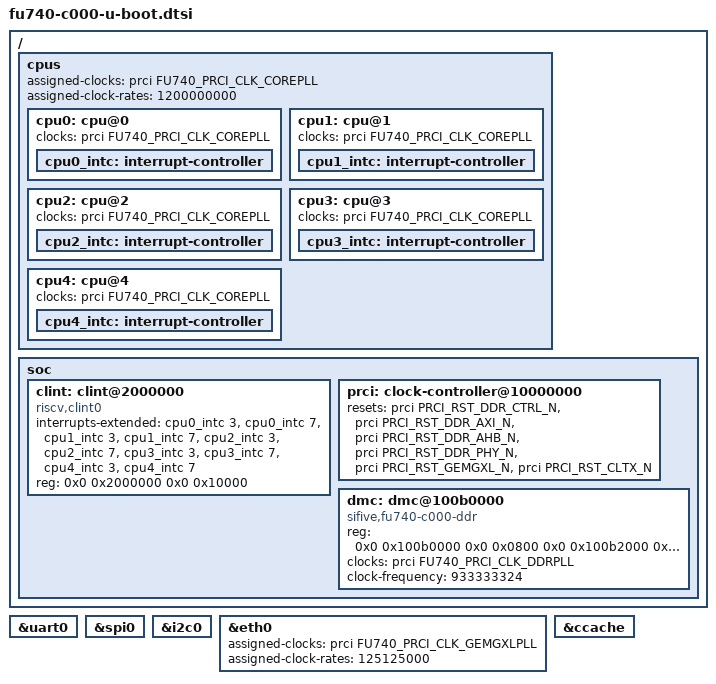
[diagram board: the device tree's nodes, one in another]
// SPDX-License-Identifier: (GPL-2.0 OR MIT)
/*
 * (C) Copyright 2020-2021 SiFive, Inc
 */

#include <dt-bindings/reset/sifive-fu740-prci.h>

/ {
	cpus {
		assigned-clocks = <&prci FU740_PRCI_CLK_COREPLL>;
		/* assigned-clock-rates = <1500000000>; */ /* 20c8e00 */
		/* assigned-clock-rates = <1000000000>; */ /* 20d12c0 */
		/* assigned-clock-rates =  <500000000>; */ /* 20d92c0 */
		/* assigned-clock-rates =  <250000000>; */ /* 20e12c0 */
		/* assigned-clock-rates =  <125000000>; */ /* 20e92c0 */
		/* assigned-clock-rates =   <62500000>; */ /* 2072282 */
		/* assigned-clock-rates = <1200000000>; */ /* 20544c2 */
		/* assigned-clock-rates =  <600000000>; */ /* 205c4c2 */
		/* assigned-clock-rates =  <300000000>; */ /* 20644c2 */
		/* assigned-clock-rates =  <150000000>; */ /* 206c4c2 */
		/* assigned-clock-rates =   <75000000>; */ /* 20744c2 */
		/* assigned-clock-rates =   <25000000>; */ /* 2072282 */
		/* assigned-clock-rates =   <13000000>; */ /* 2072282 */
		/* assigned-clock-rates =   <26000000>; */ /* 20187c1 */
		/* assigned-clock-rates =   <50000000>; */ /* 2072282 */
		/* assigned-clock-rates =   <52000000>; */ /* 2072282 */
		/* assigned-clock-rates =  <100000000>; */ /* 20e8f00 */
		/* assigned-clock-rates =  <200000000>; */ /* 20e0f00 */
		/* assigned-clock-rates =  <400000000>; */ /* 20d8f00 */
		/* assigned-clock-rates =  <800000000>; */ /* 20d0f00 */
		/* assigned-clock-rates = <1600000000>; */ /* 20c8f00 bad */
		 assigned-clock-rates = <1200000000>; 
		u-boot,dm-spl;
		cpu0: cpu@0 {
			clocks = <&prci FU740_PRCI_CLK_COREPLL>;
			u-boot,dm-spl;
			status = "okay";
			cpu0_intc: interrupt-controller {
				u-boot,dm-spl;
			};
		};
		cpu1: cpu@1 {
			clocks = <&prci FU740_PRCI_CLK_COREPLL>;
			u-boot,dm-spl;
			cpu1_intc: interrupt-controller {
				u-boot,dm-spl;
			};
		};
		cpu2: cpu@2 {
			clocks = <&prci FU740_PRCI_CLK_COREPLL>;
			u-boot,dm-spl;
			cpu2_intc: interrupt-controller {
				 u-boot,dm-spl;
			};
		};
		cpu3: cpu@3 {
			clocks = <&prci FU740_PRCI_CLK_COREPLL>;
			u-boot,dm-spl;
			cpu3_intc: interrupt-controller {
				u-boot,dm-spl;
			};
		};
		cpu4: cpu@4 {
			clocks = <&prci FU740_PRCI_CLK_COREPLL>;
			u-boot,dm-spl;
			cpu4_intc: interrupt-controller {
				u-boot,dm-spl;
			};
		};
	};

	soc {
		u-boot,dm-spl;
		clint: clint@2000000 {
			compatible = "riscv,clint0";
			interrupts-extended = <&cpu0_intc 3 &cpu0_intc 7
					       &cpu1_intc 3 &cpu1_intc 7
					       &cpu2_intc 3 &cpu2_intc 7
					       &cpu3_intc 3 &cpu3_intc 7
					       &cpu4_intc 3 &cpu4_intc 7>;
			reg = <0x0 0x2000000 0x0 0x10000>;
			u-boot,dm-spl;
		};
		prci: clock-controller@10000000 {
			#reset-cells = <1>;
			resets = <&prci PRCI_RST_DDR_CTRL_N>,
				 <&prci PRCI_RST_DDR_AXI_N>,
				 <&prci PRCI_RST_DDR_AHB_N>,
				 <&prci PRCI_RST_DDR_PHY_N>,
				 <&prci PRCI_RST_GEMGXL_N>,
				 <&prci PRCI_RST_CLTX_N>;
			reset-names = "ddr_ctrl", "ddr_axi", "ddr_ahb",
					"ddr_phy", "gemgxl_reset", "cltx_reset";
		};
		dmc: dmc@100b0000 {
			compatible = "sifive,fu740-c000-ddr";
			reg = <0x0 0x100b0000 0x0 0x0800
			       0x0 0x100b2000 0x0 0x2000
			       0x0 0x100b8000 0x0 0x1000>;
			clocks = <&prci FU740_PRCI_CLK_DDRPLL>;
			clock-frequency = <933333324>;
			u-boot,dm-spl;
		};
	};
};

&prci {
	u-boot,dm-spl;
};

&uart0 {
	u-boot,dm-spl;
};

&spi0 {
	u-boot,dm-spl;
};

&i2c0 {
	u-boot,dm-spl;
};

&eth0 {
	assigned-clocks = <&prci FU740_PRCI_CLK_GEMGXLPLL>;
	assigned-clock-rates = <125125000>;
};

&ccache {
	status = "okay";
};
